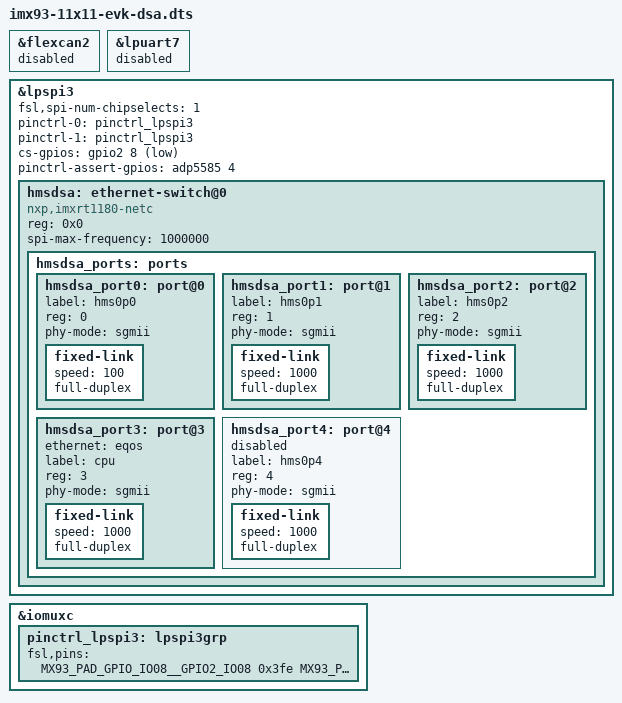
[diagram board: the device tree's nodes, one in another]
// SPDX-License-Identifier: (GPL-2.0+ OR MIT)
/*
 * Copyright 2023-2025 NXP
 */

#include "imx93-11x11-evk.dts"

&flexcan2 {
	status = "disabled";
};

&lpuart7 {
	status = "disabled";
};

&lpspi3 {
	fsl,spi-num-chipselects = <1>;
	pinctrl-names = "default", "sleep";
	pinctrl-0 = <&pinctrl_lpspi3>;
	pinctrl-1 = <&pinctrl_lpspi3>;
	cs-gpios = <&gpio2 8 GPIO_ACTIVE_LOW>;
	pinctrl-assert-gpios = <&adp5585 4 GPIO_ACTIVE_HIGH>;
	status = "okay";

	hmsdsa: ethernet-switch@0 {
		reg = <0x0>;
		#address-cells = <1>;
		#size-cells = <0>;
		compatible = "nxp,imxrt1180-netc";
		/* 1 MHz */
		spi-max-frequency = <1000000>;
		/* Sample data on trailing clock edge */

		hmsdsa_ports: ports {
			#address-cells = <1>;
			#size-cells = <0>;

			hmsdsa_port0: port@0 {
				label = "hms0p0";
				reg = <0>;
				phy-mode = "sgmii";

				fixed-link {
					speed = <100>;
					full-duplex;
				};
			};

			hmsdsa_port1: port@1 {
				label = "hms0p1";
				reg = <1>;
				phy-mode = "sgmii";

				fixed-link {
					speed = <1000>;
					full-duplex;
				};
			};

			hmsdsa_port2: port@2 {
				label = "hms0p2";
				reg = <2>;
				phy-mode = "sgmii";

				fixed-link {
					speed = <1000>;
					full-duplex;
				};
			};

			hmsdsa_port3: port@3 {
				/* cpu port connected to eqos */
				ethernet = <&eqos>;
				label = "cpu";
				reg = <3>;
				phy-mode = "sgmii";

				fixed-link {
					speed = <1000>;
					full-duplex;
				};
			};

			hmsdsa_port4: port@4 {
				label = "hms0p4";
				reg = <4>;
				phy-mode = "sgmii";
				status = "disabled";

				fixed-link {
					speed = <1000>;
					full-duplex;
				};
			};
		};
	};
};

&iomuxc {
	pinctrl_lpspi3: lpspi3grp {
		fsl,pins = <
			MX93_PAD_GPIO_IO08__GPIO2_IO08		0x3fe
			MX93_PAD_GPIO_IO09__LPSPI3_SIN		0x3fe
			MX93_PAD_GPIO_IO10__LPSPI3_SOUT		0x3fe
			MX93_PAD_GPIO_IO11__LPSPI3_SCK		0x3fe
		>;
	};
};
